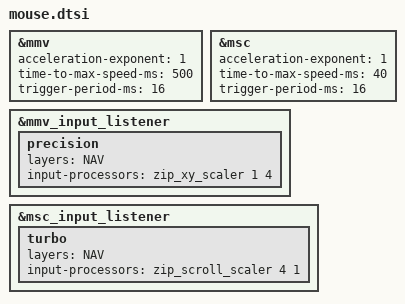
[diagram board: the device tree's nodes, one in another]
#define ZMK_POINTING_DEFAULT_MOVE_VAL 1500  // 600
#define ZMK_POINTING_DEFAULT_SCRL_VAL 200   // 10

#include <dt-bindings/zmk/pointing.h>
#include <input/processors.dtsi>

&mmv {
    acceleration-exponent = <1>;      // 1
    time-to-max-speed-ms = <500>;     // 300
    trigger-period-ms = <16>;
};

&msc {
    acceleration-exponent = <1>;      // 0
    time-to-max-speed-ms = <40>;      // 300
    trigger-period-ms = <16>;
};

&mmv_input_listener {
    precision {
        layers = <NAV>;
        input-processors = <&zip_xy_scaler 1 4>;
    };
};

&msc_input_listener {
    turbo {
        layers = <NAV>;
        input-processors = <&zip_scroll_scaler 4 1>;
    };
};
